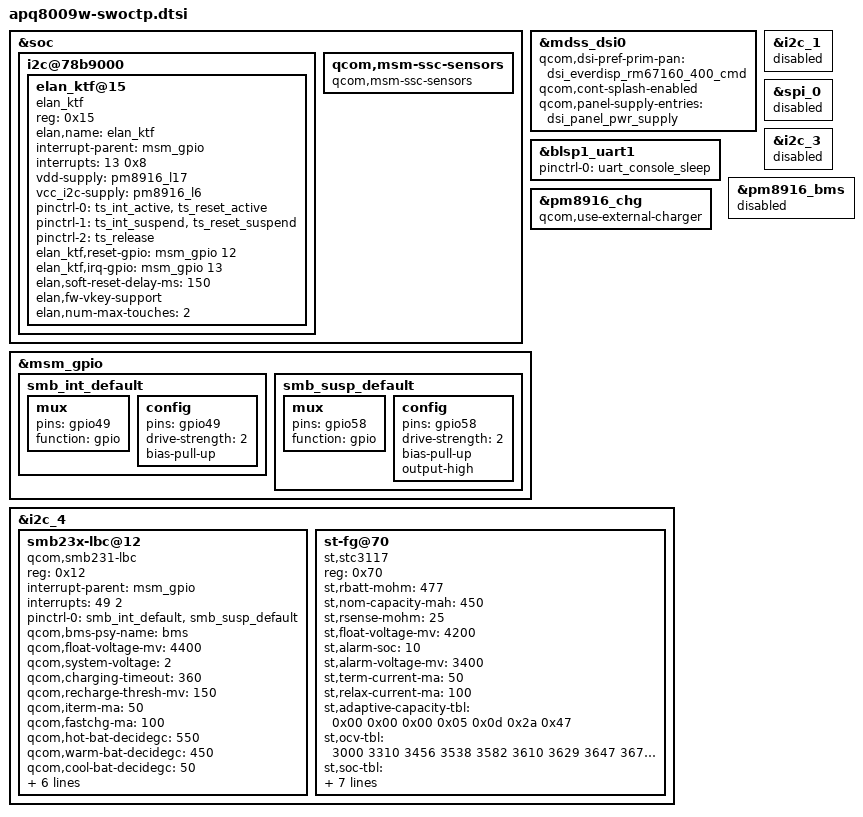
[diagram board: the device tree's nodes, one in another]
/*
 * Copyright (c) 2016, The Linux Foundation. All rights reserved.
 *
 * This program is free software; you can redistribute it and/or modify
 * it under the terms of the GNU General Public License version 2 and
 * only version 2 as published by the Free Software Foundation.
 *
 * This program is distributed in the hope that it will be useful,
 * but WITHOUT ANY WARRANTY; without even the implied warranty of
 * MERCHANTABILITY or FITNESS FOR A PARTICULAR PURPOSE.  See the
 * GNU General Public License for more details.
 */

#include "msm8909-mtp.dtsi"
#include "msm8909w-gpu.dtsi"
#include "msm8909-pm8916.dtsi"
#include "msm8909-pm8916-mtp.dtsi"
#include "msm8909w.dtsi"
#include "apq8009w-memory.dtsi"

&soc {
	i2c@78b9000 { /* BLSP1 QUP5 */
		/delete-node/ synaptics@20;

		/* Quanta BU10SW, Stanley Tsao, 2016.02.22, Porting Elan touch driver eWD1020 { */
		elan_ktf@15 {
			compatible = "elan_ktf";
			reg = <0x15>;
			elan,name = "elan_ktf";
			interrupt-parent = <&msm_gpio>;
			interrupts = <13 0x8>;
			vdd-supply = <&pm8916_l17>;
			vcc_i2c-supply = <&pm8916_l6>;
			/* pins used by touchscreen */
			pinctrl-names = "pmx_ts_active","pmx_ts_suspend","pmx_ts_release";
			pinctrl-0 = <&ts_int_active &ts_reset_active>;
			pinctrl-1 = <&ts_int_suspend &ts_reset_suspend>;
			pinctrl-2 = <&ts_release>;
			elan_ktf,reset-gpio = <&msm_gpio 12 0x00>;
			elan_ktf,irq-gpio =<&msm_gpio 13 0x00>;
			elan,soft-reset-delay-ms = <150>;
			elan,fw-vkey-support;
			elan,num-max-touches = <2>;
		};
		/* Quanta BU10SW, Stanley Tsao, 2016.02.22, Porting Elan touch driver eWD1020 } */
	};

	qcom,msm-ssc-sensors {
		compatible = "qcom,msm-ssc-sensors";
	};
};

/* Quanta BU10SW, Stanley Tsao, 2016.02.22, Add display driver for EverDisplay RM67160 400P CMD mode { */
&mdss_dsi0 {
	qcom,dsi-pref-prim-pan = <&dsi_everdisp_rm67160_400_cmd>;
	qcom,cont-splash-enabled;
	qcom,panel-supply-entries = <&dsi_panel_pwr_supply>;
};
/* Quanta BU10SW, Stanley Tsao, 2016.02.22, Add display driver for EverDisplay RM67160 400P CMD mode } */

&blsp1_uart1 {
	status = "ok";
	pinctrl-names = "default";
	pinctrl-0 = <&uart_console_sleep>;
};

&i2c_1 {
	status = "disabled";
};

&spi_0 {
	status = "disabled";
};

&i2c_3 {
	status = "disabled";
};

/* Charger/FG configuration */
&pm8916_chg {
	qcom,use-external-charger;
};

&pm8916_bms {
	status = "disabled";
};

&msm_gpio {
	/* Delete gpio58 configuration */
	/delete-node/ tpiu_seta_14;
	/delete-node/ smb_int_pin;
	smb_int_default: smb_int_default {
		mux {
			pins = "gpio49";
			function = "gpio";
		};
		config {
			pins = "gpio49";
			drive-strength = <2>;   /* 2 MA */
			bias-pull-up;           /* PULL UP*/
		};
	};

	smb_susp_default: smb_susp_default {
		mux {
			pins = "gpio58";
			function ="gpio";
		};
		config {
			pins = "gpio58";
			drive-strength = <2>;   /* 2 MA */
			bias-pull-up;           /* PULL UP*/
			output-high;
		};
	};
};

&i2c_4 {
	status = "ok";
	smb23x-lbc@12 {
		compatible = "qcom,smb231-lbc";
		reg = <0x12>;
		interrupt-parent = <&msm_gpio>;
		interrupts = <49 2>;
		pinctrl-names = "default";
		pinctrl-0 = <&smb_int_default &smb_susp_default>;

		qcom,bms-psy-name = "bms";
		qcom,float-voltage-mv = <4400>;
		qcom,system-voltage = <2>; /* 0=>4.3V(default), 1=>5.5V, 2=>VBATT+250mV, 3=>VIN */
		qcom,charging-timeout = <360>;
		qcom,recharge-thresh-mv = <150>;
		qcom,iterm-ma = <50>;
		qcom,fastchg-ma = <100>;
		qcom,hot-bat-decidegc = <550>;
		qcom,warm-bat-decidegc = <450>;
		qcom,cool-bat-decidegc = <50>;
		qcom,cold-bat-decidegc = <(-50)>;
		qcom,soft-temp-vfloat-comp-mv = <200>;
		qcom,soft-temp-current-comp-ma = <400>;
		qcom,chg-inhibit-disabled;
		qcom,apsd-disabled;
		qcom,thermal-mitigation = <1500 900 500 100>;
	};

	st-fg@70 {
		compatible = "st,stc3117";
		reg = <0x70>;
		st,rbatt-mohm = <477>;
		st,nom-capacity-mah = <450>;
		st,rsense-mohm = <25>;
		st,float-voltage-mv = <4200>;
		st,alarm-soc = <10>;
		st,alarm-voltage-mv = <3400>;
		st,term-current-ma = <50>;
		st,relax-current-ma = <100>;
		st,adaptive-capacity-tbl =
			/bits/ 16 <0x00 0x00 0x00 0x05 0x0d 0x2a 0x47>;
		st,ocv-tbl =
			/bits/ 16 <3000 3310 3456 3538 3582 3610 3629 3647 3671 3697 3758 3834 3928 4037 4158 4305>;
		st,soc-tbl = /bits/ 8 <0 3 6 10 15 20 25 30 35 40 50 60 70 80 90 100>;
		st,vmtemp-tbl =
			/bits/ 16 <0x55 0x5a 0x64 0xa0 0x140 0x1b8 0x348>;
		st,temp-tbl =
			/bits/ 16 <60 40 25 10 0 (-10) (-20)>;

		st,empty-soc-uv = <3300000>;
		qcom,fg-vadc = <&pm8916_vadc>;
		qcom,fg-adc_tm = <&pm8916_adc_tm>;
	};
};
